# ATSAMD21E15B register map
Vendor: Microchip Technology Inc.; Series: SAMD21; File version: D
CPU: CM0+ r0p1, little endian, no MPU, no FPU, VTOR, 2 interrupt priority bits, 29 interrupts
Registers are 8-bit, read-write, reset 0x0 unless marked. A register's access mark holds for its fields unless they carry their own. Offsets are from the block's base; [hi:lo] are bit positions; {n}, {i} and the like mark numbered series; 'fields as' and 'values as' point back to an identical list.

## EIC — External Interrupt Controller
Base 0x40001800; register names take the prefix EIC_
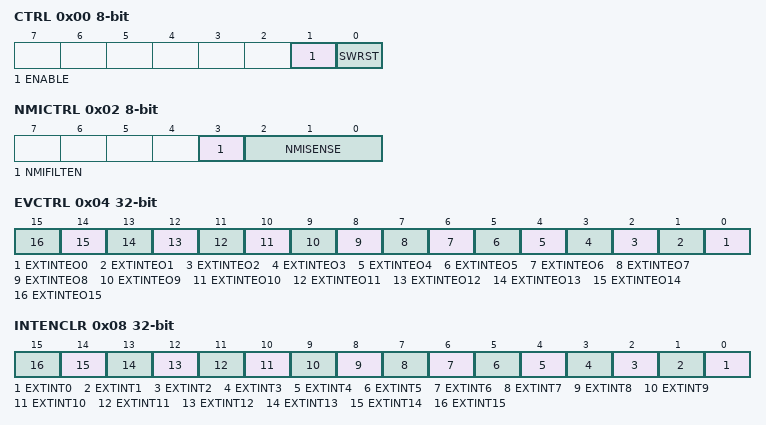
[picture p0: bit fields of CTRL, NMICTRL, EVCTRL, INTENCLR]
0x00 CTRL — Control
  [1] ENABLE
  [0] SWRST — Software Reset
0x01 STATUS ro
  [7] SYNCBUSY — Synchronization Busy
0x02 NMICTRL — Non-Maskable Interrupt Control
  [3] NMIFILTEN — Non-Maskable Interrupt Filter Enable
  [2:0] NMISENSE — Non-Maskable Interrupt Sense
    0=NONE (No detection); 1=RISE (Rising-edge detection); 2=FALL (Falling-edge detection); 3=BOTH (Both-edges detection); 4=HIGH (High-level detection); 5=LOW (Low-level detection)
0x03 NMIFLAG — Non-Maskable Interrupt Flag Status and Clear
  [0] NMI — Non-Maskable Interrupt
0x04 EVCTRL 32-bit — Event Control
  [n] EXTINTEO{n} (n=0..15) — External Interrupt {n} Event Output Enable
0x08 INTENCLR 32-bit — Interrupt Enable Clear
  [n] EXTINT{n} (n=0..15) — External Interrupt {n} Enable
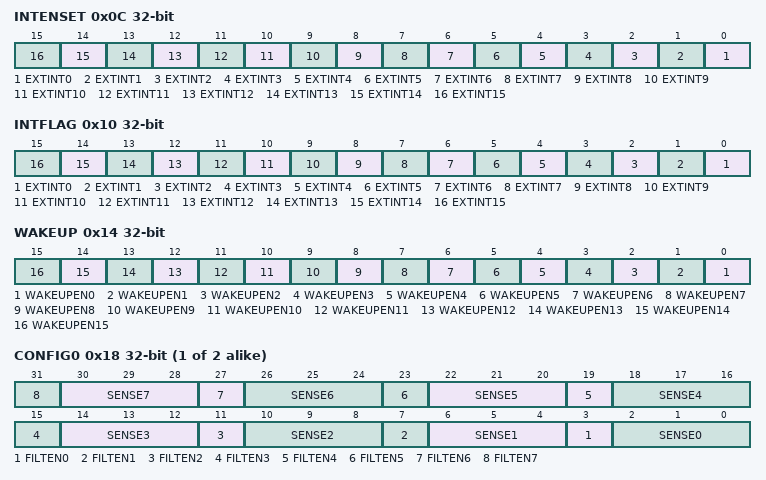
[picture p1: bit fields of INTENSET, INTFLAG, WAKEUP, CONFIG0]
0x0C INTENSET 32-bit — Interrupt Enable Set
  [n] EXTINT{n} (n=0..15) — External Interrupt {n} Enable
0x10 INTFLAG 32-bit — Interrupt Flag Status and Clear
  [n] EXTINT{n} (n=0..15) — External Interrupt {n}
0x14 WAKEUP 32-bit — Wake-Up Enable
  [n] WAKEUPEN{n} (n=0..15) — External Interrupt {n} Wake-up Enable
{0x18+4i} CONFIG{i} (i=0..1) 32-bit — Configuration n
  [4n+3] FILTEN{n} (n=0..7) — Filter {n} Enable
  [4n+2:4n] SENSE{n} (n=1..7) — Input Sense {n} Configuration
    0=NONE (No detection); 1=RISE (Rising edge detection); 2=FALL (Falling edge detection); 3=BOTH (Both edges detection); 4=HIGH (High level detection); 5=LOW (Low level detection)
  [2:0] SENSE0 — Input Sense 0 Configuration
    values as NMICTRL.NMISENSE

## EVSYS — Event System Interface
Base 0x42000400; register names take the prefix EVSYS_
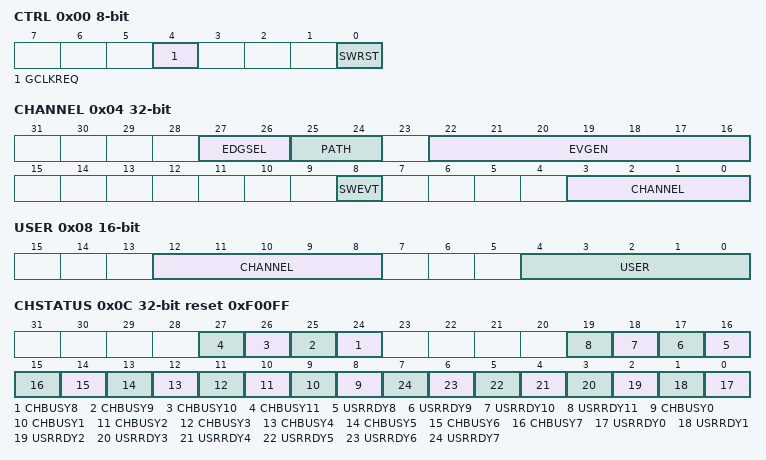
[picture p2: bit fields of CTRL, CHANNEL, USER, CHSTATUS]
0x00 CTRL wo — Control
  [4] GCLKREQ — Generic Clock Requests
  [0] SWRST — Software Reset
0x04 CHANNEL 32-bit
  [27:26] EDGSEL — Edge Detection Selection
    0=NO_EVT_OUTPUT (No event output when using the resynchronized or synchronous path); 1=RISING_EDGE (Event detection only on the rising edge of the signal from the event generator when using the resynchronized or synchronous path); 2=FALLING_EDGE (Event detection only on the falling edge of the signal from the event generator when using the resynchronized or synchronous path); 3=BOTH_EDGES (Event detection on rising and falling edges of the signal from the event generator when using the resynchronized or synchronous path)
  [25:24] PATH — Path Selection
    0=SYNCHRONOUS (Synchronous path); 1=RESYNCHRONIZED (Resynchronized path); 2=ASYNCHRONOUS (Asynchronous path)
  [22:16] EVGEN — Event Generator Selection
  [8] SWEVT — Software Event
  [3:0] CHANNEL — Channel Selection
0x08 USER 16-bit — User Multiplexer
  [12:8] CHANNEL — Channel Event Selection
    0=No Channel Output Selected
  [4:0] USER — User Multiplexer Selection
0x0C CHSTATUS 32-bit ro reset 0xF00FF — Channel Status
  [n+16] CHBUSY{n} (n=8..11) — Channel {n} Busy
  [n+8] USRRDY{n} (n=8..11) — Channel {n} User Ready
  [n+8] CHBUSY{n} (n=0..7) — Channel {n} Busy
  [n] USRRDY{n} (n=0..7) — Channel {n} User Ready
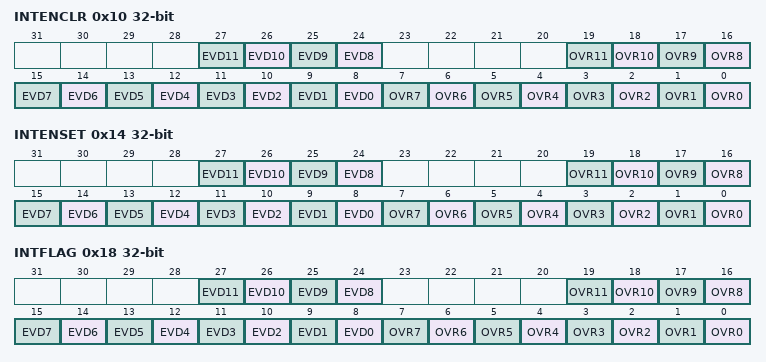
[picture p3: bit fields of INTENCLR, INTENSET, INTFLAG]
0x10 INTENCLR 32-bit — Interrupt Enable Clear
  [n+16] EVD{n} (n=8..11) — Channel {n} Event Detection Interrupt Enable
  [n+8] OVR{n} (n=8..11) — Channel {n} Overrun Interrupt Enable
  [n+8] EVD{n} (n=0..7) — Channel {n} Event Detection Interrupt Enable
  [n] OVR{n} (n=0..7) — Channel {n} Overrun Interrupt Enable
0x14 INTENSET 32-bit — Interrupt Enable Set
  fields as INTENCLR
0x18 INTFLAG 32-bit — Interrupt Flag Status and Clear
  [n+16] EVD{n} (n=8..11) — Channel {n} Event Detection
  [n+8] OVR{n} (n=8..11) — Channel {n} Overrun
  [n+8] EVD{n} (n=0..7) — Channel {n} Event Detection
  [n] OVR{n} (n=0..7) — Channel {n} Overrun

## Notices in the file
Copyright (c) 2018 Microchip Technology Inc.
SPDX-License-Identifier: Apache-2.0
Licensed under the Apache License, Version 2.0 (the "License");
you may not use this file except in compliance with the License.
You may obtain a copy of the License at
http://www.apache.org/licenses/LICENSE-2.0
Unless required by applicable law or agreed to in writing, software
distributed under the License is distributed on an "AS IS" BASIS,
WITHOUT WARRANTIES OR CONDITIONS OF ANY KIND, either express or implied.
See the License for the specific language governing permissions and
limitations under the License.
